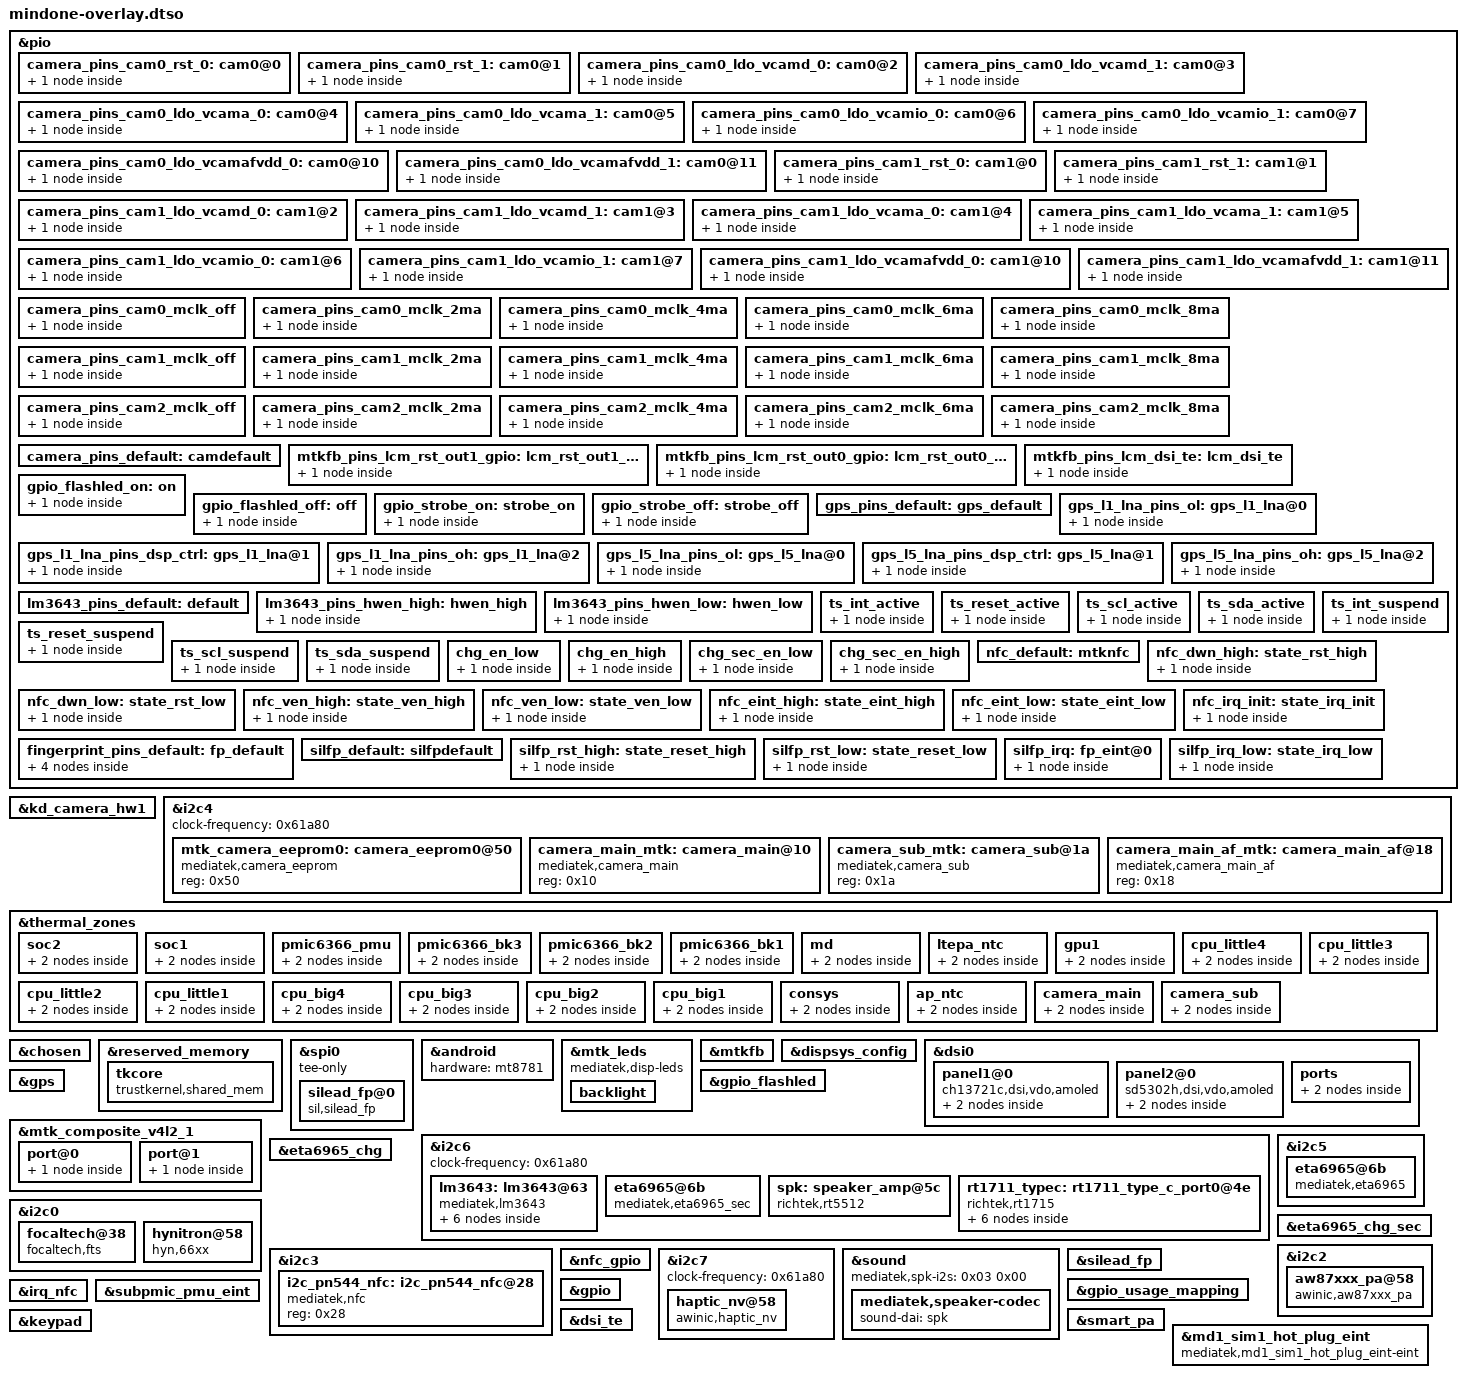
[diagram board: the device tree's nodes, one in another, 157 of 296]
/dts-v1/;
/plugin/;

&pio {
	camera_pins_cam0_rst_0: cam0@0 {
		pins_cmd_dat {
			pinmux = <0xf00>;
			slew-rate = <0x01>;
			output-low;
		};
	};

	camera_pins_cam0_rst_1: cam0@1 {
		pins_cmd_dat {
			pinmux = <0xf00>;
			slew-rate = <0x01>;
			output-high;
		};
	};

	camera_pins_cam0_ldo_vcamd_0: cam0@2 {
		pins_cmd_dat {
			pinmux = <0x1500>;
			slew-rate = <0x01>;
			output-low;
		};
	};

	camera_pins_cam0_ldo_vcamd_1: cam0@3 {
		pins_cmd_dat {
			pinmux = <0x1500>;
			slew-rate = <0x01>;
			output-high;
		};
	};

	camera_pins_cam0_ldo_vcama_0: cam0@4 {
		pins_cmd_dat {
			pinmux = <0x1300>;
			slew-rate = <0x01>;
			output-low;
		};
	};

	camera_pins_cam0_ldo_vcama_1: cam0@5 {
		pins_cmd_dat {
			pinmux = <0x1300>;
			slew-rate = <0x01>;
			output-high;
		};
	};

	camera_pins_cam0_ldo_vcamio_0: cam0@6 {
		pins_cmd_dat {
			pinmux = <0x1600>;
			slew-rate = <0x01>;
			output-low;
		};
	};

	camera_pins_cam0_ldo_vcamio_1: cam0@7 {
		pins_cmd_dat {
			pinmux = <0x1600>;
			slew-rate = <0x01>;
			output-high;
		};
	};

	camera_pins_cam0_ldo_vcamafvdd_0: cam0@10 {
		pins_cmd_dat {
			pinmux = <0x9700>;
			slew-rate = <0x01>;
			output-low;
		};
	};

	camera_pins_cam0_ldo_vcamafvdd_1: cam0@11 {
		pins_cmd_dat {
			pinmux = <0x9700>;
			slew-rate = <0x01>;
			output-high;
		};
	};

	camera_pins_cam1_rst_0: cam1@0 {
		pins_cmd_dat {
			pinmux = <0xf00>;
			slew-rate = <0x01>;
			output-low;
		};
	};

	camera_pins_cam1_rst_1: cam1@1 {
		pins_cmd_dat {
			pinmux = <0xf00>;
			slew-rate = <0x01>;
			output-high;
		};
	};

	camera_pins_cam1_ldo_vcamd_0: cam1@2 {
		pins_cmd_dat {
			pinmux = <0x1500>;
			slew-rate = <0x01>;
			output-low;
		};
	};

	camera_pins_cam1_ldo_vcamd_1: cam1@3 {
		pins_cmd_dat {
			pinmux = <0x1500>;
			slew-rate = <0x01>;
			output-high;
		};
	};

	camera_pins_cam1_ldo_vcama_0: cam1@4 {
		pins_cmd_dat {
			pinmux = <0x1300>;
			slew-rate = <0x01>;
			output-low;
		};
	};

	camera_pins_cam1_ldo_vcama_1: cam1@5 {
		pins_cmd_dat {
			pinmux = <0x1300>;
			slew-rate = <0x01>;
			output-high;
		};
	};

	camera_pins_cam1_ldo_vcamio_0: cam1@6 {
		pins_cmd_dat {
			pinmux = <0x1600>;
			slew-rate = <0x01>;
			output-low;
		};
	};

	camera_pins_cam1_ldo_vcamio_1: cam1@7 {
		pins_cmd_dat {
			pinmux = <0x1600>;
			slew-rate = <0x01>;
			output-high;
		};
	};

	camera_pins_cam1_ldo_vcamafvdd_0: cam1@10 {
		pins_cmd_dat {
			pinmux = <0x9700>;
			slew-rate = <0x01>;
			output-low;
		};
	};

	camera_pins_cam1_ldo_vcamafvdd_1: cam1@11 {
		pins_cmd_dat {
			pinmux = <0x9700>;
			slew-rate = <0x01>;
			output-high;
		};
	};

	camera_pins_cam0_mclk_off: camera_pins_cam0_mclk_off {
		pins_cmd_dat {
			pinmux = <0x7e00>;
			drive-strength = <0x01>;
		};
	};

	camera_pins_cam0_mclk_2ma: camera_pins_cam0_mclk_2ma {
		pins_cmd_dat {
			pinmux = <0x7e01>;
			drive-strength = <0x00>;
		};
	};

	camera_pins_cam0_mclk_4ma: camera_pins_cam0_mclk_4ma {
		pins_cmd_dat {
			pinmux = <0x7e01>;
			drive-strength = <0x01>;
		};
	};

	camera_pins_cam0_mclk_6ma: camera_pins_cam0_mclk_6ma {
		pins_cmd_dat {
			pinmux = <0x7e01>;
			drive-strength = <0x02>;
		};
	};

	camera_pins_cam0_mclk_8ma: camera_pins_cam0_mclk_8ma {
		pins_cmd_dat {
			pinmux = <0x7e01>;
			drive-strength = <0x03>;
		};
	};

	camera_pins_cam1_mclk_off: camera_pins_cam1_mclk_off {
		pins_cmd_dat {
			pinmux = <0x7e00>;
			drive-strength = <0x01>;
		};
	};

	camera_pins_cam1_mclk_2ma: camera_pins_cam1_mclk_2ma {
		pins_cmd_dat {
			pinmux = <0x7e01>;
			drive-strength = <0x00>;
		};
	};

	camera_pins_cam1_mclk_4ma: camera_pins_cam1_mclk_4ma {
		pins_cmd_dat {
			pinmux = <0x7e01>;
			drive-strength = <0x01>;
		};
	};

	camera_pins_cam1_mclk_6ma: camera_pins_cam1_mclk_6ma {
		pins_cmd_dat {
			pinmux = <0x7e01>;
			drive-strength = <0x02>;
		};
	};

	camera_pins_cam1_mclk_8ma: camera_pins_cam1_mclk_8ma {
		pins_cmd_dat {
			pinmux = <0x7e01>;
			drive-strength = <0x03>;
		};
	};

	camera_pins_cam2_mclk_off: camera_pins_cam2_mclk_off {
		pins_cmd_dat {
			pinmux = <0x8100>;
			drive-strength = <0x01>;
		};
	};

	camera_pins_cam2_mclk_2ma: camera_pins_cam2_mclk_2ma {
		pins_cmd_dat {
			pinmux = <0x8101>;
			drive-strength = <0x00>;
		};
	};

	camera_pins_cam2_mclk_4ma: camera_pins_cam2_mclk_4ma {
		pins_cmd_dat {
			pinmux = <0x8101>;
			drive-strength = <0x01>;
		};
	};

	camera_pins_cam2_mclk_6ma: camera_pins_cam2_mclk_6ma {
		pins_cmd_dat {
			pinmux = <0x8101>;
			drive-strength = <0x02>;
		};
	};

	camera_pins_cam2_mclk_8ma: camera_pins_cam2_mclk_8ma {
		pins_cmd_dat {
			pinmux = <0x8101>;
			drive-strength = <0x03>;
		};
	};

	camera_pins_default: camdefault {
	};
};

&kd_camera_hw1 {
	pinctrl-names = "default", "cam0_rst0", "cam0_rst1", "cam1_rst0", "cam1_rst1", "cam0_mclk_off", "cam0_mclk_2mA", "cam0_mclk_4mA", "cam0_mclk_6mA", "cam0_mclk_8mA", "cam1_mclk_off", "cam1_mclk_2mA", "cam1_mclk_4mA", "cam1_mclk_6mA", "cam1_mclk_8mA", "cam2_mclk_off", "cam2_mclk_2mA", "cam2_mclk_4mA", "cam2_mclk_6mA", "cam2_mclk_8mA", "cam0_ldo_vcama_0", "cam0_ldo_vcama_1", "cam0_ldo_vcamd_0", "cam0_ldo_vcamd_1", "cam0_ldo_vcamio_0", "cam0_ldo_vcamio_1", "cam0_ldo_vcamafvdd_0", "cam0_ldo_vcamafvdd_1", "cam1_ldo_vcama_0", "cam1_ldo_vcama_1", "cam1_ldo_vcamd_0", "cam1_ldo_vcamd_1", "cam1_ldo_vcamio_0", "cam1_ldo_vcamio_1", "cam1_ldo_vcamafvdd_0", "cam1_ldo_vcamafvdd_1";
	pinctrl-0 = <&camera_pins_default>;
	pinctrl-1 = <&camera_pins_cam0_rst_0>;
	pinctrl-2 = <&camera_pins_cam0_rst_1>;
	pinctrl-3 = <&camera_pins_cam1_rst_0>;
	pinctrl-4 = <&camera_pins_cam1_rst_1>;
	pinctrl-5 = <&camera_pins_cam0_mclk_off>;
	pinctrl-6 = <&camera_pins_cam0_mclk_2ma>;
	pinctrl-7 = <&camera_pins_cam0_mclk_4ma>;
	pinctrl-8 = <&camera_pins_cam0_mclk_6ma>;
	pinctrl-9 = <&camera_pins_cam0_mclk_8ma>;
	pinctrl-10 = <&camera_pins_cam1_mclk_off>;
	pinctrl-11 = <&camera_pins_cam1_mclk_2ma>;
	pinctrl-12 = <&camera_pins_cam1_mclk_4ma>;
	pinctrl-13 = <&camera_pins_cam1_mclk_6ma>;
	pinctrl-14 = <&camera_pins_cam1_mclk_8ma>;
	pinctrl-15 = <&camera_pins_cam2_mclk_off>;
	pinctrl-16 = <&camera_pins_cam2_mclk_2ma>;
	pinctrl-17 = <&camera_pins_cam2_mclk_4ma>;
	pinctrl-18 = <&camera_pins_cam2_mclk_6ma>;
	pinctrl-19 = <&camera_pins_cam2_mclk_8ma>;
	pinctrl-20 = <&camera_pins_cam0_ldo_vcama_0>;
	pinctrl-21 = <&camera_pins_cam0_ldo_vcama_1>;
	pinctrl-22 = <&camera_pins_cam0_ldo_vcamd_0>;
	pinctrl-23 = <&camera_pins_cam0_ldo_vcamd_1>;
	pinctrl-24 = <&camera_pins_cam0_ldo_vcamio_0>;
	pinctrl-25 = <&camera_pins_cam0_ldo_vcamio_1>;
	pinctrl-26 = <&camera_pins_cam0_ldo_vcamafvdd_0>;
	pinctrl-27 = <&camera_pins_cam0_ldo_vcamafvdd_1>;
	pinctrl-28 = <&camera_pins_cam1_ldo_vcama_0>;
	pinctrl-29 = <&camera_pins_cam1_ldo_vcama_1>;
	pinctrl-30 = <&camera_pins_cam1_ldo_vcamd_0>;
	pinctrl-31 = <&camera_pins_cam1_ldo_vcamd_1>;
	pinctrl-32 = <&camera_pins_cam1_ldo_vcamio_0>;
	pinctrl-33 = <&camera_pins_cam1_ldo_vcamio_1>;
	pinctrl-34 = <&camera_pins_cam1_ldo_vcamafvdd_0>;
	pinctrl-35 = <&camera_pins_cam1_ldo_vcamafvdd_1>;
	cam0_pin_mclk = "mclk";
	cam0_pin_rst = "gpio";
	cam0_pin_vcama = "gpio";
	cam0_pin_vcamio = "gpio";
	cam0_pin_vcamd = "gpio";
	cam0_pin_vcama1 = "regulator";
	cam0_pin_vcamaf = "gpio";
	cam1_pin_mclk = "mclk";
	cam1_pin_rst = "gpio";
	cam1_pin_vcama = "gpio";
	cam1_pin_vcamio = "gpio";
	cam1_pin_vcamd = "gpio";
	cam1_pin_vcama1 = "regulator";
	cam1_pin_vcamaf = "gpio";
	cam2_pin_mclk = "mclk";
	cam2_pin_rst = "gpio";
	cam2_pin_vcama = "regulator";
	cam2_pin_vcamio = "regulator";
	cam2_pin_vcamd = "regulator";
	cam2_pin_vcama1 = "regulator";
	cam2_pin_vcamaf = "gpio";
	status = "okay";
};

&i2c4 {
	status = "okay";
	clock-frequency = <0x61a80>;
	#address-cells = <0x01>;
	#size-cells = <0x00>;

	mtk_camera_eeprom0: camera_eeprom0@50 {
		compatible = "mediatek,camera_eeprom";
		reg = <0x50>;
		status = "okay";
	};

	camera_main_mtk: camera_main@10 {
		compatible = "mediatek,camera_main";
		#thermal-sensor-cells = <0x00>;
		reg = <0x10>;
		status = "okay";
	};

	camera_sub_mtk: camera_sub@1a {
		compatible = "mediatek,camera_sub";
		#thermal-sensor-cells = <0x00>;
		reg = <0x1a>;
		status = "okay";
	};
};

&thermal_zones {
	soc2 {
		trips {
			hot {
				type = "hot";
				hysteresis = <0x7d0>;
				temperature = <0x1c138>;
			};
		};
	};

	soc1 {
		trips {
			hot {
				type = "hot";
				hysteresis = <0x7d0>;
				temperature = <0x1c138>;
			};
		};
	};

	pmic6366_pmu {
		trips {
			hot {
				type = "hot";
				hysteresis = <0x7d0>;
				temperature = <0x1c138>;
			};
		};
	};

	pmic6366_bk3 {
		trips {
			hot {
				type = "hot";
				hysteresis = <0x7d0>;
				temperature = <0x1c138>;
			};
		};
	};

	pmic6366_bk2 {
		trips {
			hot {
				type = "hot";
				hysteresis = <0x7d0>;
				temperature = <0x1c138>;
			};
		};
	};

	pmic6366_bk1 {
		trips {
			hot {
				type = "hot";
				hysteresis = <0x7d0>;
				temperature = <0x1c138>;
			};
		};
	};

	md {
		trips {
			hot {
				type = "hot";
				hysteresis = <0x7d0>;
				temperature = <0x1c138>;
			};
		};
	};

	ltepa_ntc {
		trips {
			hot {
				type = "hot";
				hysteresis = <0x7d0>;
				temperature = <0x1c138>;
			};
		};
	};

	gpu1 {
		trips {
			hot {
				type = "hot";
				hysteresis = <0x7d0>;
				temperature = <0x1c138>;
			};
		};
	};

	cpu_little4 {
		trips {
			hot {
				type = "hot";
				hysteresis = <0x7d0>;
				temperature = <0x1c138>;
			};
		};
	};

	cpu_little3 {
		trips {
			hot {
				type = "hot";
				hysteresis = <0x7d0>;
				temperature = <0x1c138>;
			};
		};
	};

	cpu_little2 {
		trips {
			hot {
				type = "hot";
				hysteresis = <0x7d0>;
				temperature = <0x1c138>;
			};
		};
	};

	cpu_little1 {
		trips {
			hot {
				type = "hot";
				hysteresis = <0x7d0>;
				temperature = <0x1c138>;
			};
		};
	};

	cpu_big4 {
		trips {
			hot {
				type = "hot";
				hysteresis = <0x7d0>;
				temperature = <0x1c138>;
			};
		};
	};

	cpu_big3 {
		trips {
			hot {
				type = "hot";
				hysteresis = <0x7d0>;
				temperature = <0x1c138>;
			};
		};
	};

	cpu_big2 {
		trips {
			hot {
				type = "hot";
				hysteresis = <0x7d0>;
				temperature = <0x1c138>;
			};
		};
	};

	cpu_big1 {
		trips {
			hot {
				type = "hot";
				hysteresis = <0x7d0>;
				temperature = <0x1c138>;
			};
		};
	};

	consys {
		trips {
			hot {
				type = "hot";
				hysteresis = <0x7d0>;
				temperature = <0x1c138>;
			};
		};
	};

	ap_ntc {
		trips {
			hot {
				type = "hot";
				hysteresis = <0x7d0>;
				temperature = <0x1c138>;
			};
		};
	};

	camera_main: camera_main {
		polling-delay = <0x3e8>;
		polling-delay-passive = <0x00>;
		thermal-sensors = <&camera_main_mtk>;

		trips {
			hot {
				type = "hot";
				hysteresis = <0x7d0>;
				temperature = <0x1c138>;
			};
		};
	};

	camera_sub: camera_sub {
		polling-delay = <0x3e8>;
		polling-delay-passive = <0x00>;
		thermal-sensors = <&camera_sub_mtk>;

		trips {
			hot {
				type = "hot";
				hysteresis = <0x7d0>;
				temperature = <0x1c138>;
			};
		};
	};
};

&chosen {
};

&reserved_memory {
	tkcore {
		compatible = "trustkernel,shared_mem";
		no-map;
		size = <0x00 0x1000000>;
		alignment = <0x00 0x1000>;
		alloc-ranges = <0x00 0x40000000 0x00 0x80000000>;
	};
};

&spi0 {
	tee-only;
};

&android {
	hardware = "mt8781";
};

&mtk_leds {
	compatible = "mediatek,disp-leds";

	backlight {
		led_mode = <0x04>;
		pwm_config = <0x00 0x01 0x00 0x00 0x00>;
	};
};

&pio {
	mtkfb_pins_lcm_rst_out1_gpio: lcm_rst_out1_gpio {
		pins_cmd_dat {
			pinmux = <0x5500>;
			slew-rate = <0x01>;
			output-high;
		};
	};

	mtkfb_pins_lcm_rst_out0_gpio: lcm_rst_out0_gpio {
		pins_cmd_dat {
			pinmux = <0x5500>;
			slew-rate = <0x01>;
			output-low;
		};
	};

	mtkfb_pins_lcm_dsi_te: lcm_dsi_te {
		pins_cmd_dat {
			pinmux = <0x5301>;
		};
	};
};

&mtkfb {
	pinctrl-names = "lcm_rst_out1_gpio", "lcm_rst_out0_gpio", "mode_te_te";
	pinctrl-0 = <&mtkfb_pins_lcm_rst_out1_gpio>;
	pinctrl-1 = <&mtkfb_pins_lcm_rst_out0_gpio>;
	pinctrl-2 = <&mtkfb_pins_lcm_dsi_te>;
	status = "okay";
};

&dispsys_config {
	pinctrl-names = "lcm_rst_out1_gpio", "lcm_rst_out0_gpio", "mode_te_te";
	pinctrl-0 = <&mtkfb_pins_lcm_rst_out1_gpio>;
	pinctrl-1 = <&mtkfb_pins_lcm_rst_out0_gpio>;
	pinctrl-2 = <&mtkfb_pins_lcm_dsi_te>;
	status = "okay";
};

&dsi0 {
	status = "okay";
	#address-cells = <0x01>;
	#size-cells = <0x00>;

	panel1@0 {
		compatible = "ch13721c,dsi,vdo,amoled";
		reg = <0x00>;
		reset-gpios = <&pio>, <0x55 0x00>;
		avdd-en-gpios = <&pio>, <0x30 0x00>;
		disp-pwm-gpios = <&pio>, <0x54 0x00>;
		gate-ic = <0x12df>;
		pinctrl-names = "default";

		port {
			panel_in1: endpoint {
				remote-endpoint = <&dsi_out>;
			};
		};
	};

	panel2@0 {
		compatible = "sd5302h,dsi,vdo,amoled";
		reg = <0x01>;
		reset-gpios = <&pio>, <0x55 0x00>;
		avdd-en-gpios = <&pio>, <0x30 0x00>;
		disp-pwm-gpios = <&pio>, <0x54 0x00>;
		gate-ic = <0x12df>;
		pinctrl-names = "default";

		port {
			panel_in2: endpoint {
				remote-endpoint = <&dsi_out>;
			};
		};
	};

	ports {
		port {
			dsi_out: endpoint {
				remote-endpoint = <&panel_in1>;
			};
		};
	};
};

&gpio_flashled {
	pinctrl-names = "gpio_flashled_on", "gpio_flashled_off", "gpio_strobe_on", "gpio_strobe_off";
	pinctrl-0 = <&gpio_flashled_on>;
	pinctrl-1 = <&gpio_flashled_off>;
	pinctrl-2 = <&gpio_strobe_on>;
	pinctrl-3 = <&gpio_strobe_off>;
	status = "okay";
};

&pio {
	gpio_flashled_on: on {
		pins_cmd_dat {
			pinmux = <0x9a00>;
			slew-rate = <0x01>;
			output-high;
		};
	};

	gpio_flashled_off: off {
		pins_cmd_dat {
			pinmux = <0x9a00>;
			slew-rate = <0x01>;
			output-low;
		};
	};

	gpio_strobe_on: strobe_on {
		pins_cmd_dat {
			pinmux = <0x9b00>;
			slew-rate = <0x01>;
			output-high;
		};
	};

	gpio_strobe_off: strobe_off {
		pins_cmd_dat {
			pinmux = <0x9b00>;
			slew-rate = <0x01>;
			output-low;
		};
	};
};

&pio {
	gps_pins_default: gps_default {
	};

	gps_l1_lna_pins_ol: gps_l1_lna@0 {
		pins_cmd_dat {
			pinmux = <0x1900>;
			output-low;
		};
	};

	gps_l1_lna_pins_dsp_ctrl: gps_l1_lna@1 {
		pins_cmd_dat {
			pinmux = <0x1902>;
		};
	};

	gps_l1_lna_pins_oh: gps_l1_lna@2 {
		pins_cmd_dat {
			pinmux = <0x1900>;
			output-high;
		};
	};

	gps_l5_lna_pins_ol: gps_l5_lna@0 {
		pins_cmd_dat {
			pinmux = <0x1a00>;
			output-low;
		};
	};

	gps_l5_lna_pins_dsp_ctrl: gps_l5_lna@1 {
		pins_cmd_dat {
			pinmux = <0x1a02>;
		};
	};

	gps_l5_lna_pins_oh: gps_l5_lna@2 {
		pins_cmd_dat {
			pinmux = <0x1a00>;
			output-high;
		};
	};
};

&gps {
	pinctrl-names = "default", "gps_l1_lna_disable", "gps_l1_lna_dsp_ctrl", "gps_l1_lna_enable", "gps_l5_lna_disable", "gps_l5_lna_dsp_ctrl", "gps_l5_lna_enable";
	pinctrl-0 = <&gps_pins_default>;
	pinctrl-1 = <&gps_l1_lna_pins_ol>;
	pinctrl-2 = <&gps_l1_lna_pins_dsp_ctrl>;
	pinctrl-3 = <&gps_l1_lna_pins_oh>;
	pinctrl-4 = <&gps_l5_lna_pins_ol>;
	pinctrl-5 = <&gps_l5_lna_pins_dsp_ctrl>;
	pinctrl-6 = <&gps_l5_lna_pins_oh>;
	status = "okay";
};

&i2c6 {
	status = "okay";
	clock-frequency = <0x61a80>;
	#address-cells = <0x01>;
	#size-cells = <0x00>;

	lm3643: lm3643@63 {
		compatible = "mediatek,lm3643";
		reg = <0x63>;
		#cooling-cells = <0x02>;
		#address-cells = <0x01>;
		#size-cells = <0x00>;
		pinctrl-names = "default", "hwen_high", "hwen_low";
		pinctrl-0 = <&lm3643_pins_default>;
		pinctrl-1 = <&lm3643_pins_hwen_high>;
		pinctrl-2 = <&lm3643_pins_hwen_low>;
		status = "okay";

		flash@0 {
			reg = <0x00>;
			type = <0x00>;
			ct = <0x00>;
			part = <0x00>;

			port@0 {
				fl_core_0: endpoint {
					remote-endpoint = <&flashlight_0>;
				};
			};
		};

		flash@1 {
			reg = <0x01>;
			type = <0x00>;
			ct = <0x01>;
			part = <0x00>;

			port@1 {
				fl_core_1: endpoint {
					remote-endpoint = <&flashlight_1>;
				};
			};
		};
	};
};

&pio {
	lm3643_pins_default: default {
	};

	lm3643_pins_hwen_high: hwen_high {
		pins_cmd_dat {
			pinmux = <0x9d00>;
			slew-rate = <0x01>;
			output-high;
		};
	};

	lm3643_pins_hwen_low: hwen_low {
		pins_cmd_dat {
			pinmux = <0x9d00>;
			slew-rate = <0x01>;
			output-low;
		};
	};
};

&mtk_composite_v4l2_1 {
	port@0 {
		flashlight_0: endpoint {
			remote-endpoint = <&fl_core_0>;
		};
	};

	port@1 {
		flashlight_1: endpoint {
			remote-endpoint = <&fl_core_1>;
		};
	};
};

&i2c4 {
	status = "okay";
	clock-frequency = <0x61a80>;
	#address-cells = <0x01>;
	#size-cells = <0x00>;

	camera_main_af_mtk: camera_main_af@18 {
		compatible = "mediatek,camera_main_af";
		reg = <0x18>;
		status = "okay";
	};
};

&i2c0 {
	focaltech@38 {
		compatible = "focaltech,fts";
		reg = <0x38>;
		interrupt-parent = <&pio>;
		interrupts = <0x09 0x02 0x09 0x00>;
		focaltech,reset-gpio = <&pio>, <0x98 0x00>;
		focaltech,irq-gpio = <&pio>, <0x09 0x00>;
		focaltech,vdd-gpio = <&pio>, <0x99 0x00>;
		focaltech,max-touch-number = <0x0a>;
		focaltech,display-coords = <0x00 0x00 0x438 0x780>;
		status = "okay";
	};

	hynitron@58 {
		compatible = "hyn,66xx";
		reg = <0x58>;
		interrupt-parent = <&pio>;
		interrupts = <0x09 0x02 0x09 0x00>;
		reset-gpio = <&pio>, <0x98 0x00>;
		irq-gpio = <&pio>, <0x09 0x00>;
		vdd-gpio = <&pio>, <0x99 0x00>;
		pinctrl-names = "ts_active", "ts_suspend";
		pinctrl-0 = <&ts_int_active>, <&ts_reset_active>, <&ts_scl_active>, <&ts_sda_active>;
		pinctrl-1 = <&ts_int_suspend>, <&ts_reset_suspend>, <&ts_scl_suspend>, <&ts_sda_suspend>;
		max-touch-number = <0x05>;
		display-coords = <0x00 0x00 0x438 0x4d8>;
		pos-swap = <0x00>;
		posx-reverse = <0x00>;
		posy-reverse = <0x00>;
		key-number = <0x00>;
		keys = <0x8b 0x66 0x9e>;
		key-y-coord = <0x7d0>;
		key-x-coords = <0xc8 0x258 0x320>;
	};
};

&pio {
	ts_int_active: ts_int_active {
		pins_cmd_dat {
			pinmux = <0x900>;
			input-enable;
		};
	};

	ts_reset_active: ts_reset_active {
		pins_cmd_dat {
			pinmux = <0x9800>;
			output-high;
		};
	};

	ts_scl_active: ts_scl_active {
		pins_cmd_dat {
			pinmux = <0x8201>;
		};
	};

	ts_sda_active: ts_sda_active {
		pins_cmd_dat {
			pinmux = <0x8301>;
		};
	};

	ts_int_suspend: ts_int_suspend {
		pins_cmd_dat {
			pinmux = <0x900>;
			output-low;
		};
	};

	ts_reset_suspend: ts_reset_suspend {
		pins_cmd_dat {
			pinmux = <0x9800>;
			output-low;
		};
	};

	ts_scl_suspend: ts_scl_suspend {
		pins_cmd_dat {
			pinmux = <0x8200>;
			output-low;
		};
	};

	ts_sda_suspend: ts_sda_suspend {
		pins_cmd_dat {
			pinmux = <0x8300>;
			output-low;
		};
	};
};

&i2c5 {
	#address-cells = <0x01>;
	#size-cells = <0x00>;

	eta6965@6b {
		status = "okay";
		compatible = "mediatek,eta6965";
		reg = <0x6b>;
		charger_name = "primary_chg";
		alias_name = "eta6965";
		ichg = <0x16e360>;
		aicr = <0x7a120>;
		mivr = <0x44aa20>;
		ieoc = <0x30d40>;
		cv = <0x432380>;
		vmreg = <0x428740>;
		enable_te;
		enable_eoc_shdn;
	};
};

&eta6965_chg {
	interrupt-parent = <&pio>;
	pinctrl-names = "psc_chg_en_low", "psc_chg_en_high";
	pinctrl-0 = <&chg_en_low>;
	pinctrl-1 = <&chg_en_high>;
};

&pio {
	chg_en_low: chg_en_low {
		pins_cmd_dat {
			pinmux = <0x300>;
			slew-rate = <0x01>;
			bias-disable;
			output-low;
		};
	};

	chg_en_high: chg_en_high {
		pins_cmd_dat {
			pinmux = <0x300>;
			slew-rate = <0x01>;
			bias-disable;
			output-high;
		};
	};
};

&i2c6 {
	#address-cells = <0x01>;
	#size-cells = <0x00>;

	eta6965@6b {
		status = "okay";
		compatible = "mediatek,eta6965_sec";
		reg = <0x6b>;
		charger_name = "secondary_chg";
		alias_name = "eta6965_sec";
		ichg = <0x16e360>;
		aicr = <0x7a120>;
		mivr = <0x44aa20>;
		ieoc = <0x30d40>;
		cv = <0x432380>;
		vmreg = <0x428740>;
		enable_te;
		enable_eoc_shdn;
	};
};

&eta6965_chg_sec {
	interrupt-parent = <&pio>;
	pinctrl-names = "psc_chg_en_low", "psc_chg_en_high";
	pinctrl-0 = <&chg_sec_en_low>;
	pinctrl-1 = <&chg_sec_en_high>;
};

&pio {
	chg_sec_en_low: chg_sec_en_low {
		pins_cmd_dat {
			pinmux = <0x9e00>;
			slew-rate = <0x01>;
			bias-disable;
			output-high;
		};
	};

	chg_sec_en_high: chg_sec_en_high {
		pins_cmd_dat {
			pinmux = <0x9e00>;
			slew-rate = <0x01>;
			bias-disable;
			output-low;
		};
	};
};

&i2c2 {
	#address-cells = <0x01>;
	#size-cells = <0x00>;

	aw87xxx_pa@58 {
		compatible = "awinic,aw87xxx_pa";
		#sound-dai-cells = <0x00>;
		reg = <0x58>;
		dev_index = <0x00>;
		status = "okay";
	};
};

&i2c3 {
	i2c_pn544_nfc: i2c_pn544_nfc@28 {
		compatible = "mediatek,nfc";
		reg = <0x28>;
		status = "okay";
	};
};

&nfc_gpio {
	interrupt-parent = <&pio>;
	pinctrl-names = "mtknfc", "ven_high", "ven_low", "dwn_high", "dwn_low", "eint_high", "eint_low", "irq_init";
	pinctrl-0 = <&nfc_default>;
	pinctrl-1 = <&nfc_ven_high>;
	pinctrl-2 = <&nfc_ven_low>;
	pinctrl-3 = <&nfc_dwn_high>;
	pinctrl-4 = <&nfc_dwn_low>;
	pinctrl-5 = <&nfc_eint_high>;
	pinctrl-6 = <&nfc_eint_low>;
	pinctrl-7 = <&nfc_irq_init>;
};

&pio {
	nfc_default: mtknfc {
	};

	nfc_dwn_high: state_rst_high {
		pins_cmd_dat {
			pinmux = <0xc00>;
			slew-rate = <0x01>;
			output-high;
		};
	};

	nfc_dwn_low: state_rst_low {
		pins_cmd_dat {
			pinmux = <0xc00>;
			slew-rate = <0x01>;
			output-low;
		};
	};

	nfc_ven_high: state_ven_high {
		pins_cmd_dat {
			pinmux = <0x9600>;
			slew-rate = <0x01>;
			output-high;
		};
	};

	nfc_ven_low: state_ven_low {
		pins_cmd_dat {
			pinmux = <0x9600>;
			slew-rate = <0x01>;
			output-low;
		};
	};

	nfc_eint_high: state_eint_high {
		pins_cmd_dat {
			pinmux = <0x100>;
			slew-rate = <0x01>;
			output-high;
		};
	};

	nfc_eint_low: state_eint_low {
		pins_cmd_dat {
			pinmux = <0x100>;
			slew-rate = <0x01>;
			output-low;
		};
	};

	nfc_irq_init: state_irq_init {
		pins_cmd_dat {
			pinmux = <0x100>;
			slew-rate = <0x00>;
			bias-pull-down = <0x00>;
		};
	};
};

&i2c7 {
	clock-frequency = <0x61a80>;
	status = "ok";
	#address-cells = <0x01>;
	#size-cells = <0x00>;

	haptic_nv@58 {
		compatible = "awinic,haptic_nv";
		reg = <0x58>;
		aw862xx_i2c_addr = <0x58>;
		reset-gpio = <&pio>, <0x9c 0x00>;
		irq-gpio = <&pio>, <0x08 0x00>;
		aw862x_vib_lk_f0_cali = <0x00>;
		aw862x_vib_mode = <0x02>;
		aw862x_vib_f0_pre = <0x6a4>;
		aw862x_vib_f0_cali_percen = <0x07>;
		aw862x_vib_cont_drv_lev = <0x7d>;
		aw862x_vib_cont_drv_lvl_ov = <0x9b>;
		aw862x_vib_cont_td = <0xf06c>;
		aw862x_vib_cont_zc_thr = <0x8f8>;
		aw862x_vib_cont_num_brk = <0x03>;
		aw862x_vib_f0_coeff = <0x104>;
		aw862x_vib_brake_cont_config = <0x01 0x01 0x5a 0x2a 0x14 0x05 0x02 0x02 0x00 0x00 0x00 0x00 0x00 0x00 0x00 0x00 0x00 0x00 0x00 0x00 0x00 0x00 0x00 0x00>;
		aw862x_vib_f0_trace_parameter = <0x05 0x03 0x02 0x0f>;
		aw862x_vib_bemf_config = <0x10 0x08 0x23 0xf8>;
		aw862x_vib_sw_brake = <0x2c 0x08>;
		aw862x_vib_trig_config = <0x00 0x01 0x00 0x01 0x01>;
		aw862x_vib_tset = <0x11>;
		aw862x_vib_duration_time = <0x14 0x1e 0x3c>;
		aw862xx_gain_bypass = <0x01>;
		aw862xx_vib_lk_f0_cali = <0x00>;
		aw862xx_vib_mode = <0x02>;
		aw862xx_vib_f0_pre = <0x514>;
		aw862xx_vib_f0_cali_percen = <0x07>;
		aw862xx_vib_cont_drv1_lvl = <0x7f>;
		aw862xx_vib_lra_vrms = <0x4b0>;
		aw862xx_vib_cont_brk_time = <0x06>;
		aw862xx_vib_cont_brk_gain = <0x08>;
		aw862xx_vib_cont_drv1_time = <0x04>;
		aw862xx_vib_cont_drv2_time = <0x14>;
		aw862xx_vib_cont_track_margin = <0x0f>;
		aw862xx_vib_d2s_gain = <0x05>;
		aw862xx_vib_trig_config = <0x00 0x00 0x00 0x01 0x00 0x02 0x00 0x00 0x00 0x00 0x01 0x00 0x02 0x00 0x00 0x00 0x00 0x01 0x00 0x02 0x00>;
		aw862xx_vib_duration_time = <0x14 0x1e 0x3c>;
		aw862xx_vib_is_enabled_track_en;
		aw8623x_gain_bypass = <0x01>;
		aw8623x_vib_lk_f0_cali = <0x00>;
		aw8623x_vib_mode = <0x02>;
		aw8623x_vib_f0_pre = <0x6a4>;
		aw8623x_vib_f0_cali_percen = <0x07>;
		aw8623x_vib_cont_drv1_lvl = <0x7f>;
		aw8623x_vib_lra_vrms = <0x3e8>;
		aw8623x_vib_cont_brk_time = <0x06>;
		aw8623x_vib_cont_brk_gain = <0x08>;
		aw8623x_vib_cont_drv1_time = <0x04>;
		aw8623x_vib_cont_drv2_time = <0x14>;
		aw8623x_vib_cont_track_margin = <0x0f>;
		aw8623x_vib_d2s_gain = <0x05>;
		aw8623x_vib_trig_config = <0x00 0x00 0x00 0x01 0x00 0x02 0x00 0x00 0x00 0x00 0x01 0x00 0x02 0x00 0x00 0x00 0x00 0x01 0x00 0x02 0x00>;
		aw8623x_vib_duration_time = <0x14 0x1e 0x3c>;
		aw8623x_vib_is_enabled_track_en;
		aw8624x_gain_bypass = <0x01>;
		aw8624x_vib_lk_f0_cali = <0x00>;
		aw8624x_vib_mode = <0x02>;
		aw8624x_vib_f0_pre = <0x6a4>;
		aw8624x_vib_f0_cali_percen = <0x0f>;
		aw8624x_vib_cont_drv1_lvl = <0x7f>;
		aw8624x_vib_lra_vrms = <0x3e8>;
		aw8624x_vib_cont_brk_time = <0x06>;
		aw8624x_vib_cont_brk_gain = <0x08>;
		aw8624x_vib_cont_drv1_time = <0x04>;
		aw8624x_vib_cont_drv2_time = <0x14>;
		aw8624x_vib_cont_track_margin = <0x0f>;
		aw8624x_vib_d2s_gain = <0x05>;
		aw8624x_vib_f0_d2s_gain = <0x01>;
		aw8624x_vib_trig_config = <0x00 0x00 0x00 0x01 0x00 0x02 0x00 0x00 0x00 0x00 0x01 0x00 0x02 0x00 0x00 0x00 0x00 0x01 0x00 0x02 0x00>;
		aw8624x_vib_duration_time = <0x14 0x1e 0x3c>;
		aw8624x_vib_is_enabled_track_en;
		aw8624x_vib_is_enabled_inter_brake;
		status = "okay";
	};
};

&i2c6 {
	spk: speaker_amp@5c {
		compatible = "richtek,rt5512";
		#sound-dai-cells = <0x00>;
		reg = <0x5c>;
		status = "okay";
		sound-name-prefix = "Left";
	};
};

&sound {
	mediatek,spk-i2s = <0x03 0x00>;

	mediatek,speaker-codec {
		sound-dai = <&spk>;
	};
};

&spi0 {
	#address-cells = <0x01>;
	#size-cells = <0x00>;
	status = "okay";

	silead_fp@0 {
		compatible = "sil,silead_fp";
		reg = <0x00>;
		spi-max-frequency = <0x7a1200>;
		status = "okay";
	};
};

&silead_fp {
	pinctrl-names = "default", "rst-low", "rst-high", "irq-init", "spi-default", "irq-low";
	pinctrl-0 = <&silfp_default>;
	pinctrl-1 = <&silfp_rst_low>;
	pinctrl-2 = <&silfp_rst_high>;
	pinctrl-3 = <&silfp_irq>;
	pinctrl-4 = <&fingerprint_pins_default>;
	pinctrl-5 = <&silfp_irq_low>;
	status = "okay";
};

&silead_fp {
	interrupt-parent = <&pio>;
	interrupts = <0x00 0x01 0x00 0x00>;
	status = "okay";
};

&pio {
	fingerprint_pins_default: fp_default {
		pins_cmd_dat {
			pinmux = <0x1f01>;
			slew-rate = <0x01>;
			bias-pull-up;
		};

		pins_cmd2_dat {
			pinmux = <0x1e01>;
			slew-rate = <0x01>;
			bias-pull-down;
		};

		pins_cmd3_dat {
			pinmux = <0x2101>;
			slew-rate = <0x00>;
			bias-pull-down;
		};

		pins_cmd4_dat {
			pinmux = <0x2001>;
			slew-rate = <0x01>;
			bias-pull-down;
		};
	};
};

&pio {
	silfp_default: silfpdefault {
	};

	silfp_rst_high: state_reset_high {
		pins_cmd_dat {
			pinmux = <0x9d00>;
			slew-rate = <0x01>;
			output-high;
		};
	};

	silfp_rst_low: state_reset_low {
		pins_cmd_dat {
			pinmux = <0x9d00>;
			slew-rate = <0x01>;
			output-low;
		};
	};

	silfp_irq: fp_eint@0 {
		pins_cmd_dat {
			pinmux = <0x00>;
			slew-rate = <0x00>;
			bias-pull-down = <0x00>;
		};
	};

	silfp_irq_low: state_irq_low {
		pins_cmd_dat {
			pinmux = <0x00>;
			slew-rate = <0x01>;
			output-low;
		};
	};
};

&gpio_usage_mapping {
	GPIO_SIM1_HOT_PLUG = <&pio>, <0x17 0x00>;
	GPIO_SIM1_SCLK = <&pio>, <0x4d 0x00>;
	GPIO_SIM1_SRST = <&pio>, <0x4e 0x00>;
	GPIO_SIM1_SIO = <&pio>, <0x4f 0x00>;
	GPIO_SIM2_SCLK = <&pio>, <0x50 0x00>;
	GPIO_SIM2_SRST = <&pio>, <0x51 0x00>;
	GPIO_SIM2_SIO = <&pio>, <0x52 0x00>;
	GPIO_FDD_BAND_SUPPORT_DETECT_1ST_PIN = <&pio>, <0x6f 0x00>;
};

&gpio {
	gpio_init_default = <0x00 0x00 0x00 0x00 0x01 0x01 0x01 0x01 0x00 0x00 0x00 0x01 0x01 0x01 0x02 0x00 0x00 0x00 0x01 0x00 0x01 0x03 0x00 0x01 0x00 0x01 0x00 0x01 0x04 0x00 0x00 0x00 0x01 0x01 0x01 0x05 0x00 0x00 0x00 0x01 0x01 0x01 0x06 0x00 0x00 0x00 0x01 0x01 0x01 0x07 0x00 0x00 0x00 0x00 0x00 0x01 0x08 0x00 0x00 0x00 0x01 0x01 0x01 0x09 0x00 0x00 0x00 0x01 0x01 0x01 0x0a 0x00 0x00 0x00 0x00 0x00 0x01 0x0b 0x00 0x00 0x00 0x01 0x01 0x01 0x0c 0x00 0x01 0x00 0x01 0x00 0x01 0x0d 0x00 0x00 0x00 0x01 0x01 0x01 0x0e 0x00 0x00 0x00 0x01 0x01 0x00 0x0f 0x00 0x01 0x00 0x01 0x00 0x00 0x10 0x00 0x01 0x00 0x01 0x00 0x00 0x11 0x00 0x00 0x00 0x01 0x00 0x00 0x12 0x00 0x01 0x00 0x01 0x00 0x00 0x13 0x00 0x01 0x00 0x01 0x00 0x00 0x14 0x00 0x01 0x00 0x01 0x00 0x00 0x15 0x00 0x01 0x00 0x01 0x00 0x00 0x16 0x00 0x01 0x00 0x01 0x00 0x00 0x17 0x01 0x00 0x00 0x01 0x01 0x00 0x18 0x00 0x00 0x00 0x01 0x00 0x00 0x19 0x02 0x00 0x00 0x01 0x00 0x01 0x1a 0x02 0x00 0x00 0x01 0x00 0x01 0x1b 0x01 0x00 0x00 0x01 0x00 0x01 0x1c 0x01 0x00 0x00 0x01 0x01 0x01 0x1d 0x01 0x00 0x00 0x00 0x00 0x01 0x1e 0x01 0x00 0x00 0x00 0x00 0x01 0x1f 0x01 0x00 0x00 0x00 0x00 0x01 0x20 0x01 0x00 0x00 0x00 0x00 0x01 0x21 0x01 0x00 0x00 0x01 0x00 0x01 0x22 0x06 0x00 0x00 0x01 0x00 0x00 0x23 0x06 0x00 0x00 0x01 0x00 0x00 0x24 0x06 0x00 0x00 0x00 0x00 0x00 0x25 0x06 0x00 0x00 0x01 0x00 0x00 0x26 0x02 0x00 0x00 0x00 0x00 0x01 0x27 0x02 0x00 0x00 0x00 0x00 0x01 0x28 0x02 0x00 0x00 0x00 0x00 0x01 0x29 0x02 0x00 0x00 0x01 0x00 0x01 0x2a 0x04 0x00 0x00 0x01 0x01 0x00 0x2b 0x04 0x00 0x00 0x00 0x00 0x00 0x2c 0x04 0x00 0x00 0x01 0x01 0x00 0x2d 0x04 0x00 0x00 0x00 0x00 0x00 0x2e 0x06 0x00 0x00 0x01 0x00 0x00 0x2f 0x06 0x00 0x00 0x01 0x00 0x00 0x30 0x00 0x01 0x00 0x01 0x00 0x00 0x31 0x06 0x00 0x00 0x01 0x00 0x00 0x32 0x02 0x00 0x00 0x00 0x00 0x01 0x33 0x02 0x00 0x00 0x00 0x00 0x01 0x34 0x02 0x00 0x00 0x00 0x00 0x01 0x35 0x02 0x00 0x00 0x01 0x00 0x01 0x42 0x01 0x00 0x00 0x01 0x01 0x00 0x43 0x01 0x00 0x00 0x01 0x01 0x01 0x44 0x01 0x00 0x00 0x01 0x01 0x01 0x45 0x01 0x00 0x00 0x01 0x01 0x01 0x4d 0x01 0x00 0x00 0x00 0x00 0x01 0x4e 0x01 0x00 0x00 0x00 0x00 0x01 0x4f 0x01 0x00 0x00 0x01 0x01 0x01 0x50 0x01 0x00 0x00 0x00 0x00 0x01 0x51 0x01 0x00 0x00 0x00 0x00 0x01 0x52 0x01 0x00 0x00 0x01 0x01 0x01 0x53 0x01 0x00 0x00 0x01 0x00 0x01 0x54 0x00 0x01 0x00 0x01 0x00 0x01 0x55 0x01 0x00 0x00 0x00 0x00 0x01 0x56 0x01 0x00 0x00 0x01 0x00 0x00 0x57 0x01 0x00 0x00 0x01 0x00 0x00 0x58 0x01 0x00 0x00 0x01 0x00 0x00 0x59 0x01 0x00 0x00 0x01 0x00 0x00 0x5a 0x01 0x00 0x00 0x01 0x00 0x00 0x5b 0x01 0x00 0x00 0x01 0x00 0x00 0x5c 0x01 0x00 0x00 0x01 0x00 0x00 0x5d 0x01 0x00 0x00 0x01 0x00 0x00 0x5e 0x01 0x00 0x00 0x01 0x00 0x00 0x5f 0x01 0x00 0x00 0x01 0x00 0x00 0x60 0x01 0x00 0x00 0x01 0x00 0x00 0x61 0x01 0x00 0x00 0x01 0x00 0x00 0x62 0x01 0x00 0x00 0x01 0x00 0x00 0x63 0x01 0x00 0x00 0x01 0x00 0x00 0x64 0x00 0x00 0x00 0x01 0x00 0x00 0x65 0x00 0x00 0x00 0x01 0x00 0x00 0x66 0x01 0x00 0x00 0x01 0x00 0x00 0x67 0x02 0x00 0x00 0x01 0x00 0x00 0x68 0x02 0x00 0x00 0x00 0x00 0x00 0x69 0x01 0x00 0x00 0x01 0x00 0x00 0x6a 0x01 0x00 0x00 0x01 0x00 0x00 0x6b 0x01 0x00 0x00 0x01 0x00 0x00 0x6c 0x01 0x00 0x00 0x01 0x00 0x00 0x6d 0x01 0x00 0x00 0x01 0x00 0x00 0x6e 0x01 0x00 0x00 0x01 0x00 0x00 0x6f 0x00 0x00 0x00 0x00 0x00 0x00 0x70 0x01 0x00 0x00 0x00 0x00 0x00 0x71 0x01 0x00 0x00 0x01 0x00 0x00 0x72 0x01 0x00 0x00 0x00 0x00 0x00 0x73 0x01 0x00 0x00 0x01 0x00 0x00 0x74 0x01 0x00 0x00 0x00 0x00 0x00 0x75 0x01 0x00 0x00 0x01 0x00 0x00 0x76 0x01 0x00 0x00 0x00 0x00 0x00 0x77 0x01 0x00 0x00 0x01 0x00 0x00 0x78 0x01 0x00 0x00 0x00 0x00 0x00 0x79 0x01 0x00 0x00 0x01 0x00 0x00 0x7a 0x01 0x00 0x00 0x00 0x00 0x00 0x7b 0x01 0x00 0x00 0x00 0x00 0x00 0x7c 0x01 0x00 0x00 0x01 0x00 0x00 0x7d 0x01 0x00 0x00 0x01 0x00 0x00 0x7e 0x01 0x00 0x00 0x01 0x00 0x00 0x7f 0x01 0x00 0x00 0x01 0x00 0x00 0x80 0x01 0x00 0x00 0x01 0x00 0x00 0x81 0x01 0x00 0x00 0x01 0x00 0x00 0x82 0x01 0x00 0x00 0x01 0x01 0x01 0x83 0x01 0x00 0x00 0x01 0x01 0x01 0x84 0x02 0x00 0x00 0x01 0x01 0x00 0x85 0x02 0x00 0x00 0x01 0x01 0x00 0x86 0x01 0x00 0x00 0x01 0x01 0x01 0x87 0x01 0x00 0x00 0x01 0x01 0x01 0x88 0x01 0x00 0x00 0x01 0x01 0x01 0x89 0x01 0x00 0x00 0x01 0x01 0x01 0x8a 0x01 0x00 0x00 0x01 0x01 0x01 0x8b 0x01 0x00 0x00 0x01 0x01 0x01 0x8c 0x01 0x00 0x00 0x01 0x01 0x01 0x8d 0x01 0x00 0x00 0x01 0x01 0x01 0x8e 0x01 0x00 0x00 0x01 0x01 0x01 0x8f 0x01 0x00 0x00 0x01 0x01 0x01 0x90 0x01 0x00 0x00 0x01 0x01 0x01 0x91 0x01 0x00 0x00 0x01 0x01 0x01 0x92 0x01 0x00 0x00 0x01 0x01 0x01 0x93 0x01 0x00 0x00 0x01 0x01 0x01 0x94 0x02 0x00 0x00 0x01 0x01 0x01 0x95 0x02 0x00 0x00 0x01 0x01 0x01 0x96 0x00 0x01 0x00 0x01 0x00 0x01 0x97 0x00 0x01 0x00 0x01 0x00 0x01 0x98 0x00 0x01 0x00 0x01 0x00 0x01 0x99 0x00 0x01 0x00 0x01 0x00 0x01 0x9a 0x00 0x01 0x00 0x01 0x00 0x01 0x9b 0x00 0x01 0x00 0x01 0x00 0x01 0x9c 0x00 0x01 0x00 0x01 0x00 0x01 0x9d 0x00 0x01 0x00 0x01 0x00 0x01 0x9e 0x00 0x01 0x00 0x01 0x00 0x00 0x9f 0x00 0x01 0x00 0x01 0x00 0x00 0xa0 0x01 0x00 0x00 0x00 0x00 0x01 0xa1 0x01 0x00 0x00 0x00 0x00 0x01 0xa2 0x01 0x00 0x00 0x00 0x00 0x01 0xa3 0x01 0x00 0x00 0x01 0x00 0x01 0xa4 0x01 0x00 0x00 0x00 0x00 0x01 0xa5 0x01 0x00 0x00 0x00 0x00 0x01 0xa6 0x01 0x00 0x00 0x00 0x00 0x01 0xa7 0x01 0x00 0x00 0x01 0x00 0x01 0xa8 0x01 0x00 0x00 0x00 0x00 0x00 0xa9 0x01 0x00 0x00 0x00 0x00 0x01 0xaa 0x01 0x00 0x00 0x00 0x00 0x01 0xab 0x01 0x00 0x00 0x00 0x00 0x01 0xac 0x01 0x00 0x00 0x00 0x00 0x01 0xad 0x01 0x00 0x00 0x01 0x00 0x01 0xae 0x01 0x00 0x00 0x01 0x00 0x01 0xaf 0x01 0x00 0x00 0x01 0x00 0x01 0xb0 0x01 0x00 0x00 0x01 0x00 0x01 0xb1 0x00 0x00 0x00 0x01 0x00 0x00 0xb2 0x00 0x00 0x00 0x01 0x00 0x00 0xb3 0x00 0x00 0x00 0x01 0x00 0x00 0xb4 0x00 0x00 0x00 0x01 0x00 0x00 0xb5 0x00 0x00 0x00 0x01 0x00 0x00 0xb6 0x00 0x00 0x00 0x01 0x00 0x00 0xb7 0x00 0x00 0x00 0x01 0x00 0x00 0xb8 0x00 0x00 0x00 0x01 0x00 0x00 0xb9 0x00 0x00 0x00 0x01 0x00 0x00 0xba 0x01 0x00 0x00 0x01 0x01 0x01 0xbb 0x01 0x00 0x00 0x01 0x01 0x01 0xbc 0x00 0x00 0x00 0x01 0x00 0x00 0xbd 0x00 0x00 0x00 0x01 0x00 0x00 0xbe 0x00 0x00 0x00 0x01 0x00 0x00 0xbf 0x00 0x00 0x00 0x01 0x00 0x00 0xc0 0x00 0x00 0x00 0x01 0x00 0x00 0xc1 0x00 0x00 0x00 0x01 0x00 0x00 0xc2 0x00 0x00 0x00 0x01 0x00 0x00 0xc3 0x00 0x00 0x00 0x01 0x00 0x00 0xc4 0x00 0x00 0x00 0x01 0x00 0x00 0xc5 0x00 0x00 0x00 0x01 0x00 0x00 0xc6 0x00 0x00 0x00 0x01 0x00 0x00 0xc7 0x00 0x00 0x00 0x01 0x00 0x00 0xc8 0x00 0x00 0x00 0x01 0x00 0x00 0xc9 0x00 0x00 0x00 0x01 0x00 0x00 0xca 0x00 0x00 0x00 0x01 0x00 0x00 0xcb 0x00 0x00 0x00 0x01 0x00 0x00 0xcc 0x00 0x00 0x00 0x01 0x00 0x00 0xcd 0x00 0x00 0x00 0x01 0x00 0x00 0xce 0x00 0x00 0x00 0x01 0x00 0x00 0xcf 0x00 0x00 0x00 0x01 0x00 0x00 0xd0 0x00 0x00 0x00 0x01 0x00 0x00 0xd1 0x00 0x00 0x00 0x01 0x00 0x00 0xd2 0x00 0x00 0x00 0x01 0x00 0x00 0xd3 0x00 0x00 0x00 0x01 0x00 0x00 0xd4 0x00 0x00 0x00 0x01 0x00 0x00 0xd5 0x00 0x00 0x00 0x01 0x00 0x00 0xd6 0x00 0x00 0x00 0x01 0x00 0x00 0xd7 0x00 0x00 0x00 0x01 0x00 0x00 0xd8 0x00 0x00 0x00 0x01 0x00 0x00 0xd9 0x00 0x00 0x00 0x01 0x00 0x00 0xda 0x00 0x00 0x00 0x01 0x00 0x00 0xdb 0x00 0x00 0x00 0x01 0x00 0x00 0xdc 0x00 0x00 0x00 0x01 0x00 0x00 0xdd 0x00 0x00 0x00 0x01 0x00 0x00>;
};

&irq_nfc {
	interrupt-parent = <&pio>;
	interrupts = <0x01 0x04>;
	status = "okay";
};

&subpmic_pmu_eint {
	interrupt-parent = <&pio>;
	interrupts = <0x04 0x08>;
	status = "okay";
};

&smart_pa {
	interrupt-parent = <&pio>;
	interrupts = <0x06 0x08>;
	status = "okay";
};

&dsi_te {
	interrupt-parent = <&pio>;
	interrupts = <0x53 0x01>;
	status = "okay";
};

&md1_sim1_hot_plug_eint {
	compatible = "mediatek,md1_sim1_hot_plug_eint-eint";
	interrupts = <0x00 0x08>;
	debounce = <0x00 0x2710>;
	dedicated = <0x00 0x00>;
	src_pin = <0x00 0x01>;
	sockettype = <0x00 0x00>;
	status = "okay";
};

&keypad {
	mediatek,key-debounce = <0x400>;
	mediatek,sw-pwrkey = <0x74>;
	mediatek,hw-pwrkey = <0x08>;
	mediatek,sw-rstkey = <0x66>;
	mediatek,hw-rstkey = <0x11>;
	mediatek,use-extend-type = <0x00>;
	mediatek,hw-map-num = <0x48>;
	mediatek,hw-init-map = <0x72 0xd4 0x00 0x00 0x00 0x00 0x00 0x00 0x00 0x73 0x00 0x00 0x00 0x00 0x00 0x00 0x00 0x00 0x00 0x00 0x00 0x00 0x00 0x00 0x00 0x00 0x00 0x00 0x00 0x00 0x00 0x00 0x00 0x00 0x00 0x00 0x00 0x00 0x00 0x00 0x00 0x00 0x00 0x00 0x00 0x00 0x00 0x00 0x00 0x00 0x00 0x00 0x00 0x00 0x00 0x00 0x00 0x00 0x00 0x00 0x00 0x00 0x00 0x00 0x00 0x00 0x00 0x00 0x00 0x00 0x00 0x00>;
	mediatek,pwrkey-eint-gpio = <0x00>;
	mediatek,pwkey-gpio-din = <0x00>;
	mediatek,hw-dl-key0 = <0x09>;
	mediatek,hw-dl-key1 = <0x00>;
	mediatek,hw-dl-key2 = <0x08>;
	mediatek,hw-recovery-key = <0x09>;
	mediatek,hw-factory-key = <0x00>;
	status = "okay";
};

&i2c6 {
	rt1711_typec: rt1711_type_c_port0@4e {
		compatible = "richtek,rt1715";
		status = "okay";
		reg = <0x4e>;
		rt-tcpc,name = "type_c_port0";
		rt-tcpc,role_def = <0x05>;
		rt-tcpc,rp_level = <0x00>;
		rt-tcpc,vconn_supply = <0x01>;
		rt-tcpc,notifier_supply_num = <0x03>;
		rt1711pd,intr_gpio = <&pio>, <0x0d 0x00>;
		rt1711pd,intr_gpio_num = <0x0d>;

		pd-data {
			pd,vid = <0x29cf>;
			pd,pid = <0x1711>;
			pd,source-cap-ext = [cf 29 11 17 00 00 00 00 00 00 00 00 00 00 00 00 00 00 00 00 00 00 01 02 00];
			pd,mfrs = "RichtekTCPC";
			pd,charging_policy = <0x31>;
			pd,source-pdo-size = <0x01>;
			pd,source-pdo-data = <0x19032>;
			pd,sink-pdo-size = <0x02>;
			pd,sink-pdo-data = <0x1912c 0x2d0c8>;
			pd,id-vdo-size = <0x03>;
			pd,id-vdo-data = <0x4029cf 0x00 0x17110000>;
			bat,nr = <0x01>;
			pd,country_nr = <0x00>;

			bat-info0 {
				bat,vid = <0x29cf>;
				bat,pid = <0x1711>;
				bat,mfrs = "bat1";
				bat,design_cap = <0xbb8>;
			};
		};

		dpm_caps {
			local_dr_power;
			local_dr_data;
			local_no_suspend;
			local_vconn_supply;
			attempt_enter_dp_mode;
			attempt_discover_cable;
			attempt_discover_id;
			pr_check = <0x00>;
			dr_check = <0x00>;
		};

		displayport {
			1st_connection = "dfp_d";
			2nd_connection = "dfp_d";
			signal,dp_v13;
			typec,receptacle;

			ufp_d {
			};

			dfp_d {
				pin_assignment,mode_c;
				pin_assignment,mode_d;
				pin_assignment,mode_e;
			};
		};
	};
};
